# iND83216 register map
Vendor: Indiemicro; Series: RealplumTiny; File version: 1.00
CPU: CM0 r0p1, selectable endian, no MPU, no FPU, 4 interrupt priority bits
Registers are 32-bit, read-write, no defined reset value unless marked. A register's access mark holds for its fields unless they carry their own. Offsets are from the block's base; [hi:lo] are bit positions.

## CRGA — Clock & Reset Generator
Base 0x50000000; register names take the prefix CRGA_
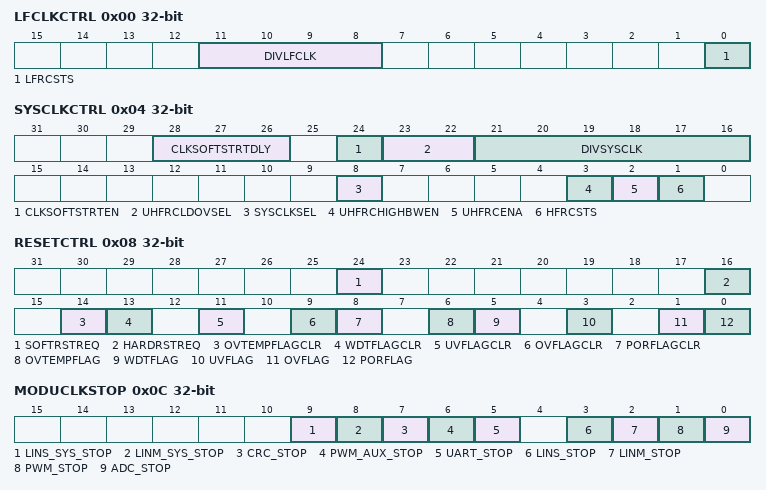
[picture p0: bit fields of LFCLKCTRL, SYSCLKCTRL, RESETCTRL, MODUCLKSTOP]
0x00 LFCLKCTRL — Low frequency clock control
  [11:8] DIVLFCLK — Low Frequency Clock div select. Select the divider ratio on the low Frequency clock when using slow oscillator. Divider ratio is (DIV_LFCLK + 1). Configure with writting trim key
  [0] LFRCSTS ro — Slow oscillator status. Will be high when the Low Frequency oscillator is selected
0x04 SYSCLKCTRL — System clock control
  [28:26] CLKSOFTSTRTDLY — Define the duration of cycles of each divider ratio when soft starting. NOTE: Fast clock selected by SEL_FASTCLK must have been enabled (HF_RC_ENA or UHF_RC_ENA) when change this field.0x0: 2 divided clock0x1: 4 divided clock0x2: 8 divided clock0x3: 16 divided clock0x4: 32 divided clock0x5: 64 divided clock0x6: 128 divided clock0x7: 256 divided clock
  [24] CLKSOFTSTRTEN — Enable Clock Soft Starter when change SYSCLKSEL from 0 to 1 for switching to fast clock. When enabled, soft starter will start the clock divider with the maximum divider ratio. And decrease divider ratio by one after staying for predefined number of cycles defined in register field CLKSOFTSTRTDLY. This operation will stop when divider ratio is equal with DIVSYSCLK. NOTE: Fast clock selected by SEL_FASTCLK must have been enabled (HF_RC_ENA or UHF_RC_ENA) when change this field.
  [23:22] UHFRCLDOVSEL — 48MHz RC OSC (UHF Oscillator) LDO output select.0x0: 1V45 Selected0x1: 1V50 Selected0x2: 1V55 Selected0x3: 1V65 Selected
  [21:16] DIVSYSCLK — Clock div select. Select the divider ratio on the system clock when using fast oscillator.0x0: No Division. Full Clock speed.0x1: Div by 2.0x2: Div by 3.0x3: Div by 4.0x4: Div by 5.0x5: Div by 6.0x6: Div by 7.0x7: Div by 8.0x3f: Div by 64.
  [8] SYSCLKSEL — System clock select. Used to switch between the fast and slow system clocks NOTE: This bit will be set by hardware after normal POR.0x0: Slow clock0x1: Fast clock
  [3] UHFRCHIGHBWEN — Ultra high frequency oscillator comparator high bandwidth enable.
  [2] UHFRCENA — Ultra high frequency oscillator enable. Setting this bit when the Ultra High Frequency oscillator is not running will cause the oscillator to start. This bit is cleared automatically on entering DeepSleep or Hibernate mode. NOTE: UHF oscillator will be stable in 100us after enabled. It is recommended switch to this clock source after it is stable.
  [1] HFRCSTS ro — Fast oscillator status. Will be high when High Frequency oscillator is enabled or fast clock is selected as system clock
0x08 RESETCTRL — Reset control
  [24] SOFTRSTREQ wo — Soft reset request. Set to trigger a soft reset of chip. Reset all modules in PDLV domain and LINS moduleAutoclear: includes a synchronous reset signal which clears the register on the cycle following write.
  [16] HARDRSTREQ wo — Hard reset request. Set to trigger a hard reset of chip
  [14] OVTEMPFLAGCLR wo — OVTEMP flag clear. Set to clear the OVTEMP flag
  [13] WDTFLAGCLR wo — WDT flag clear. Set to clear the WDT flag
  [11] UVFLAGCLR wo — UV flag clear. Set to clear the UV flag
  [9] OVFLAGCLR wo — OV flag clear. Set to clear the OV flag
  [8] PORFLAGCLR wo — POR flag clear. Set to clear the POR flag
  [6] OVTEMPFLAG ro — Over Temp Violation flag. Set by the hardware when the over temp condition is detected.
  [5] WDTFLAG ro — Watchdog bark flag. Set by the hardware when the watchdog barks.
  [3] UVFLAG ro — Under Voltage Monitor flag. Set by the hardware when the under voltage monitor.
  [1] OVFLAG ro — Over Voltage Monitor flag. Set by the hardware when the over voltage monitor.
  [0] PORFLAG ro — Power on reset flag. Set by the hardware during power-on reset
0x0C MODUCLKSTOP — Module Clock Stop
  [9] LINS_SYS_STOP — Force to stop the clock of the Bus idle timeout monitor in module, 1: stop is valid; 0: stop is invalid
  [8] LINM_SYS_STOP — Force to stop the clock of the Bus idle timeout monitor in module, 1: stop is valid; 0: stop is invalid
  [7] CRC_STOP — Force to stop the clock of the module, 1: stop is valid; 0: stop is invalid. N.A. in realplum-hp.
  [6] PWM_AUX_STOP — Force to stop the clock of the module, 1: stop is valid; 0: stop is invalid
  [5] UART_STOP — Force to stop the clock of the module, 1: stop is valid; 0: stop is invalid
  [3] LINS_STOP — Force to stop the clock of the module, 1: stop is valid; 0: stop is invalid
  [2] LINM_STOP — Force to stop the clock of the module, 1: stop is valid; 0: stop is invalid
  [1] PWM_STOP — Force to stop the clock of the module, 1: stop is valid; 0: stop is invalid
  [0] ADC_STOP — Force to stop the clock of the module, 1: stop is valid; 0: stop is invalid
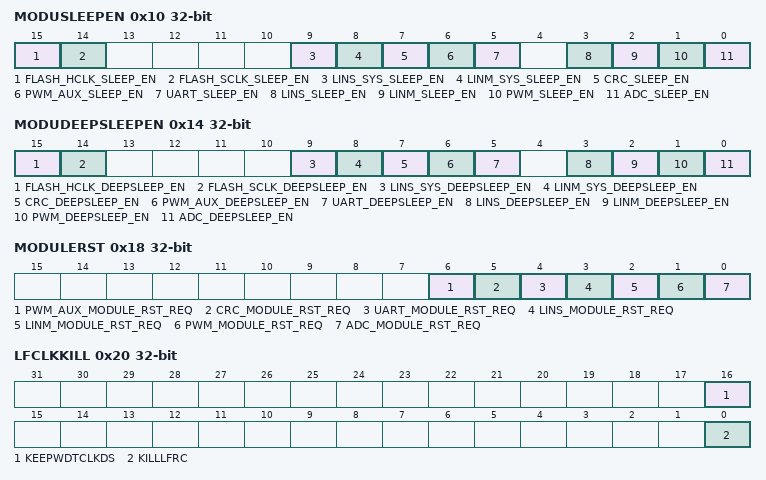
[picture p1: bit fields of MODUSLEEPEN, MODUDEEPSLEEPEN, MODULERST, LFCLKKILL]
0x10 MODUSLEEPEN — Module Clock Gated in CPU Sleep Mode
  [15] FLASH_HCLK_SLEEP_EN — Flash HCLK Gated in CPU Sleep Mode. Gate the module ahb clock when CPU has entered sleep, 1: gate is valid; 0: gate is invalid. N.A. in realplum-hp.
  [14] FLASH_SCLK_SLEEP_EN — Flash SCLK Gated in CPU Sleep Mode. Gate the module state clock when CPU has entered sleep, 1: gate is valid; 0: gate is invalid. N.A. in realplum-hp. SCLK is not Gated by default
  [9] LINS_SYS_SLEEP_EN — For Bus idle timeout monitor clock Gated in CPU Sleep Mode. Gate the module clock when CPU has entered sleep, 1: gate is valid; 0: gate is invalid
  [8] LINM_SYS_SLEEP_EN — For Bus idle timeout monitor clock Gated in CPU Sleep Mode. Gate the module clock when CPU has entered sleep, 1: gate is valid; 0: gate is invalid
  [7] CRC_SLEEP_EN — Gate the module clock when CPU has entered sleep, 1: gate is valid; 0: gate is invalid. N.A. in realplum-hp.
  [6] PWM_AUX_SLEEP_EN — Gate the module clock when CPU has entered sleep, 1: gate is valid; 0: gate is invalid
  [5] UART_SLEEP_EN — Gate the module clock when CPU has entered sleep, 1: gate is valid; 0: gate is invalid
  [3] LINS_SLEEP_EN — Gate the module clock when CPU has entered sleep, 1: gate is valid; 0: gate is invalid
  [2] LINM_SLEEP_EN — Gate the module clock when CPU has entered sleep, 1: gate is valid; 0: gate is invalid
  [1] PWM_SLEEP_EN — Gate the module clock when CPU has entered sleep, 1: gate is valid; 0: gate is invalid
  [0] ADC_SLEEP_EN — Gate the module clock when CPU has entered sleep, 1: gate is valid; 0: gate is invalid
0x14 MODUDEEPSLEEPEN — Module Clock Gated in CPU Deep Sleep Mode
  [15] FLASH_HCLK_DEEPSLEEP_EN — Flash HCLK Gated in CPU Deep Sleep Mode. Gate the module ahb clock when CPU has entered deep sleep, 1: gate is valid; 0: gate is invalid. N.A. in realplum-hp
  [14] FLASH_SCLK_DEEPSLEEP_EN — Flash SCLK Gated in CPU Deep Sleep Mode. Gate the module state clock when CPU has entered deep sleep, 1: gate is valid; 0: gate is invalid. N.A. in realplum-hp SCLK is not Gated by default
  [9] LINS_SYS_DEEPSLEEP_EN — For Bus idle timeout monitor clock Gated in CPU Deep Sleep Mode. Gate the module clock when CPU has entered deep sleep, 1: gate is valid; 0: gate is invalid
  [8] LINM_SYS_DEEPSLEEP_EN — For Bus idle timeout monitor clock Gated in CPU Deep Sleep Mode. Gate the module clock when CPU has entered deep sleep, 1: gate is valid; 0: gate is invalid
  [7] CRC_DEEPSLEEP_EN — Gate the module clock when CPU has entered deep sleep, 1: gate is valid; 0: gate is invalid. N.A. in realplum-hp.
  [6] PWM_AUX_DEEPSLEEP_EN — Gate the module clock when CPU has entered deep sleep, 1: gate is valid; 0: gate is invalid
  [5] UART_DEEPSLEEP_EN — Gate the module clock when CPU has entered deep sleep, 1: gate is valid; 0: gate is invalid
  [3] LINS_DEEPSLEEP_EN — Gate the module clock when CPU has entered deep sleep, 1: gate is valid; 0: gate is invalid
  [2] LINM_DEEPSLEEP_EN — Gate the module clock when CPU has entered deep sleep, 1: gate is valid; 0: gate is invalid
  [1] PWM_DEEPSLEEP_EN — Gate the module clock when CPU has entered deep sleep, 1: gate is valid; 0: gate is invalid
  [0] ADC_DEEPSLEEP_EN — Gate the module clock when CPU has entered deep sleep, 1: gate is valid; 0: gate is invalid
0x18 MODULERST — Module Reset control
  [6] PWM_AUX_MODULE_RST_REQ — PWM_AUX Soft reset requestAutoclear: includes a synchronous reset signal which clears the register on the cycle following write.
  [5] CRC_MODULE_RST_REQ — CRC Soft reset requestAutoclear: includes a synchronous reset signal which clears the register on the cycle following write.
  [4] UART_MODULE_RST_REQ — UART Soft reset requestAutoclear: includes a synchronous reset signal which clears the register on the cycle following write.
  [3] LINS_MODULE_RST_REQ — LIN Slave Soft reset requestAutoclear: includes a synchronous reset signal which clears the register on the cycle following write.
  [2] LINM_MODULE_RST_REQ — LIN Master reset requestAutoclear: includes a synchronous reset signal which clears the register on the cycle following write.
  [1] PWM_MODULE_RST_REQ — PWM Soft reset requestAutoclear: includes a synchronous reset signal which clears the register on the cycle following write.
  [0] ADC_MODULE_RST_REQ — ADC Soft reset requestAutoclear: includes a synchronous reset signal which clears the register on the cycle following write.
0x1C WDTACTION — Watchdog action
  [0] WDTACTION — Watchdog action. Defines the consequences of watchdog bark being detected by the hardware.0x0: IRQ generated0x1: Hard reset generated
0x20 LFCLKKILL — Low frequency clock kill
  [16] KEEPWDTCLKDS — Keep WDT clock in Deepsleep. Set to keep WDT clock running in deepsleep mode.
  [0] KILLLFRC — Kill slow RC oscillator. Setting this bit gates the low frequency RC oscillator input
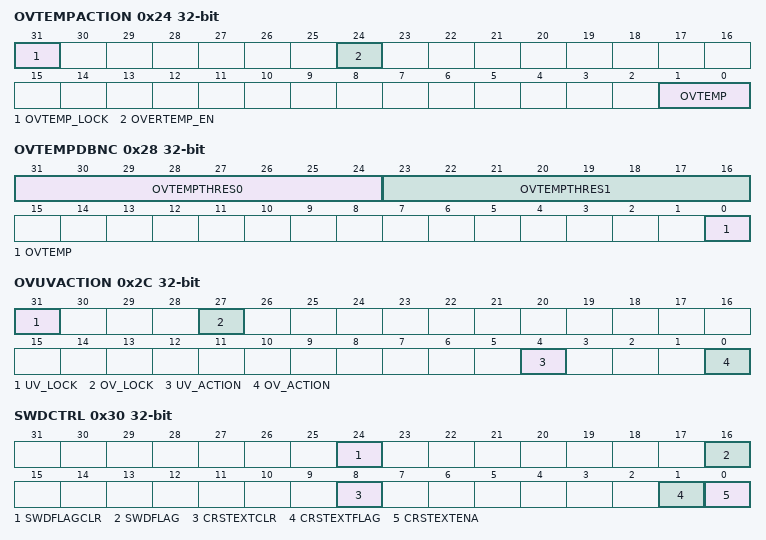
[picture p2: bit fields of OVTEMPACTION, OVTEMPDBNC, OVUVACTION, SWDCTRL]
0x24 OVTEMPACTION
  [31] OVTEMP_LOCK — Set Only bit. Set this bit to lock OVTEMP related bits.
  [24] OVERTEMP_EN — OverTemp Monitor Enable bit.
  [1:0] OVTEMP — Over Temperature action. Defines the consequences of over temp condition detected by the hardware.0x2: No action0x1: IRQ generated0x0: Hard reset generated
0x28 OVTEMPDBNC — OVTEMP Debounce Register
  [31:24] OVTEMPTHRES0 — Over Voltage debouncing threshold for 1to0 Transition. Sets the threshold for debouncing the over voltage event going from 1 to 0. It will require the ovtemp flag to stay high for the (OVTEMPTHRES0+1) number of LF clocks(4us) to transit from a 1 to 0.
  [23:16] OVTEMPTHRES1 — Under Voltage debouncing threshold for 0to1 Transition. Sets the threshold for debouncing the under voltage event going from 0 to 1. It will require the ovtemp flag to stay high for the (OVTEMPTHRES1+1) number of LF clocks(4us) to transit from a 0 to 1.
  [0] OVTEMP — ovtemp flag signal debounce enable. if set to '1, debounces the under voltage signal before going to under voltage interrupt generation else the signal bypass the debouncer
0x2C OVUVACTION
  [31] UV_LOCK — Set Only bit. Set this bit to lock UV_ACTION related bits.
  [27] OV_LOCK — Set Only bit. Set this bit to lock OV_ACTION related bits.
  [4] UV_ACTION — Under Voltage action. Defines the consequences of under voltage condition detected by the hardware.0x1: No action0x0: Hard reset generated
  [0] OV_ACTION — Over Voltage action. Defines the consequences of over voltage condition detected by the hardware.0x1: No action0x0: Hard reset generated
0x30 SWDCTRL — Swd debug control
  [24] SWDFLAGCLR wo — SWD Wakeup flag clear. Set to clear the SWD Wakeup flag
  [16] SWDFLAG ro — SWD wakeup flag. Set by the hardware when chip is awakened by SWD from deepsleep mode and clear through SWDFLAGCLR.
  [8] CRSTEXTCLR wo — M0 core extend reset clear. clear M0 core extend reset
  [1] CRSTEXTFLAG ro — M0 core extend reset flag. Set by the hardware when: 1) both CRSTEXTENA and SWDFLAG are high; or 2) SWCLK is high when power up or exit from hibernate or exit from deepsleep. Clear through CRSTEXTCLR. CPU core will hold in reset state until this bit is cleared.
  [0] CRSTEXTENA — M0 core extend reset enable. enable M0 core extented reset when chip is awakened by SWD from deepsleep mode
